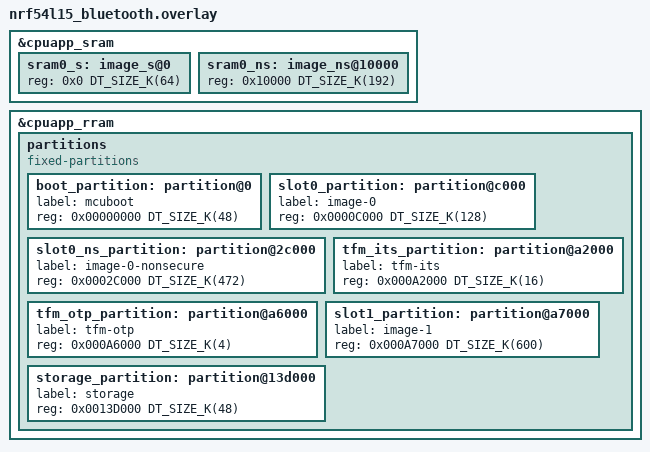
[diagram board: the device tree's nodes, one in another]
/*
 * Copyright (c) 2026 Nordic Semiconductor ASA
 *
 * SPDX-License-Identifier: LicenseRef-Nordic-5-Clause
 */

/*
 * Bluetooth-optimized TF-M partition layout for nRF54L15
 *
 * nRF54L15 has 1524 kB of RRAM and 256 kB of SRAM.
 * TrustZone flash region alignment: 4 kB (MPC-based)
 * TrustZone RAM region alignment:   4 kB
 * RRAM erase-block-size:            4 kB
 *
 * Optimized for Bluetooth LE applications with:
 * - Medium TF-M secure partition (crypto for BLE pairing/bonding)
 * - MCUboot for DFU over BLE (SMP/FOTA)
 * - ITS for BLE bond storage
 * - Larger NS partition for BLE stack + application
 * - NVS storage for BLE settings persistence
 *
 * Suitable for: BLE peripherals, BLE mesh nodes, wearables
 */

&cpuapp_sram {
	sram0_s: image_s@0 {
		#address-cells = <1>;
		#size-cells = <1>;
		reg = <0x0 DT_SIZE_K(64)>;
		ranges = <0x0 0x0 DT_SIZE_K(64)>;
	};

	sram0_ns: image_ns@10000 {
		#address-cells = <1>;
		#size-cells = <1>;
		reg = <0x10000 DT_SIZE_K(192)>;
		ranges = <0x0 0x10000 DT_SIZE_K(192)>;
	};
};

&cpuapp_rram {
	partitions {
		compatible = "fixed-partitions";
		#address-cells = <1>;
		#size-cells = <1>;

		/*
		 * Flash layout (all addresses 4 kB aligned):
		 *
		 * 0x00000000  MCUboot bootloader        (48 kB)
		 * 0x0000C000  Primary slot:
		 *   0x0000C000  TF-M secure image       (128 kB)
		 *   0x0002C000  Non-secure BLE app       (472 kB)
		 * 0x000A2000  TF-M ITS                   (16 kB)
		 * 0x000A6000  TF-M OTP / NV counters      (4 kB)
		 * 0x000A7000  Secondary slot             (600 kB)
		 * 0x0013D000  Non-secure storage (NVS)    (48 kB)
		 *
		 * No TF-M PS partition — BLE bonds are stored in ITS or NVS.
		 * NS storage enlarged for BLE bond/settings persistence.
		 */

		boot_partition: partition@0 {
			label = "mcuboot";
			reg = <0x00000000 DT_SIZE_K(48)>;
		};

		slot0_partition: partition@c000 {
			label = "image-0";
			reg = <0x0000C000 DT_SIZE_K(128)>;
		};

		slot0_ns_partition: partition@2c000 {
			label = "image-0-nonsecure";
			reg = <0x0002C000 DT_SIZE_K(472)>;
		};

		tfm_its_partition: partition@a2000 {
			label = "tfm-its";
			reg = <0x000A2000 DT_SIZE_K(16)>;
		};

		tfm_otp_partition: partition@a6000 {
			label = "tfm-otp";
			reg = <0x000A6000 DT_SIZE_K(4)>;
		};

		slot1_partition: partition@a7000 {
			label = "image-1";
			reg = <0x000A7000 DT_SIZE_K(600)>;
		};

		storage_partition: partition@13d000 {
			label = "storage";
			reg = <0x0013D000 DT_SIZE_K(48)>;
		};
	};
};
